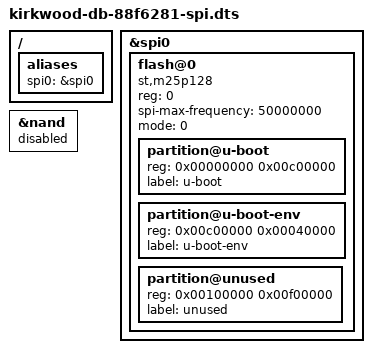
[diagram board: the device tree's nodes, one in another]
// SPDX-License-Identifier: GPL-2.0
/*
 * Marvell DB-88F6281-BP Development Board Setup
 *
 * Saeed Bishara <saeed@marvell.com>
 * Thomas Petazzoni <thomas.petazzoni@free-electrons.com>
 *
 */

/dts-v1/;

#include "kirkwood-db-88f6281.dts"

/ {
	aliases {
		spi0 = &spi0;
	};
};

&spi0 {
	status = "okay";

	flash@0 {
		#address-cells = <1>;
		#size-cells = <1>;
		compatible = "st,m25p128", "jedec,spi-nor", "spi-flash";
		reg = <0>;
		spi-max-frequency = <50000000>;
		mode = <0>;

		partition@u-boot {
			reg = <0x00000000 0x00c00000>;
			label = "u-boot";
		};
		partition@u-boot-env {
			reg = <0x00c00000 0x00040000>;
			label = "u-boot-env";
		};
		partition@unused {
			reg = <0x00100000 0x00f00000>;
			label = "unused";
		};
	};
};

&nand {
	status = "disabled";
};
